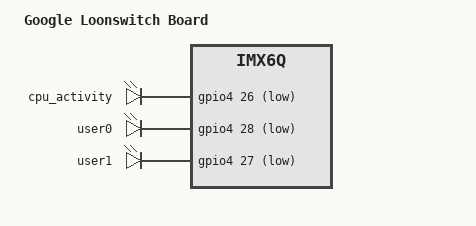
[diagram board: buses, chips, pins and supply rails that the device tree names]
/*
 * Copyright 2013 Freescale Semiconductor, Inc.
 *
 * Author: Fabio Estevam <fabio.estevam@freescale.com>
 *
 * This program is free software; you can redistribute it and/or modify
 * it under the terms of the GNU General Public License version 2 as
 * published by the Free Software Foundation.
 *
 */
/dts-v1/;
#include "imx6q.dtsi"
#include "imx6qdl-loonswitch.dtsi"
#include <dt-bindings/gpio/gpio.h>

/ {
	model = "Google Loonswitch Board";
	compatible = "fsl,imx6q";

	leds {
		compatible = "gpio-leds";
		cpuact {
			label = "cpu_activity";
			gpios = <&gpio4 26 1>;
			linux,default-trigger = "heartbeat";
			default-state = "on";
		};
		user0 {
			label = "user0";
			gpios = <&gpio4 28 1>;
			default-state = "on";
		};
		user1 {
			label = "user1";
			gpios = <&gpio4 27 1>;
			default-state = "on";
		};
	};
};

&iomuxc {
	pinctrl-names = "default";
	pinctrl-0 = <&pinctrl_hog>;

	hog {
		pinctrl_hog: hoggrp {
			fs,pins = <
				MX6QDL_PAD_EIM_RW__GPIO2_IO26		0x80000000	/* OUTPUT, BCM_PWREN, ACTIVE HIGH */
				MX6QDL_PAD_EIM_OE__GPIO2_IO25		0x80000000	/* OUTPUT, WIFI_5V_PWREN, ACTIVE HIGH */
				MX6QDL_PAD_EIM_CS0__GPIO2_IO23		0x80000000	/* OUTPUT, WIFI_PWREN, ACTIVE HIGH */
				MX6QDL_PAD_EIM_CS1__GPIO2_IO24		0x80000000	/* INPUT, LM5056_ALERTn, ACTIVE LOW */
				MX6QDL_PAD_SD1_DAT1__GPIO1_IO17 	0x80000000	/* OUTPUT, HEATER_DISABLE, ACTIVE HIGH */
				MX6QDL_PAD_KEY_COL0__GPIO4_IO06 	0x80000000	/* OUTPUT, CAN LOOPBACK, ACTIVE HIGH */
				MX6QDL_PAD_ENET_RXD0__GPIO1_IO27	0x80000000	/* INPUT, PEX_ERR#, ACTIVE LOW */
				MX6QDL_PAD_GPIO_7__GPIO1_IO07		0x80000000	/* INPUT, I210_ALERTN, ACTIVE LOW */
				MX6QDL_PAD_GPIO_8__GPIO1_IO08		0x80000000	/* INPUT, OCS_N2, ACTIVE LOW */
				MX6QDL_PAD_GPIO_9__GPIO1_IO09		0x80000000	/* OUTPUT, SC_RESET, ACTIVE HIGH */
				MX6QDL_PAD_GPIO_16__GPIO7_IO11		0x80000000	/* INPUT, I210_WAKEN, ACTIVE LOW */
				MX6QDL_PAD_GPIO_18__GPIO7_IO13		0x80000000	/* INPUT, PEX_INTA#, ACTIVE LOW */
				MX6QDL_PAD_GPIO_19__GPIO4_IO05		0x80000000	/* OUTPUT, USB_HUB_RESET_B, ACTIVE LOW */
				MX6QDL_PAD_NANDF_CS0__GPIO6_IO11	0x80000000	/* INPUT, CON_GPIO0, ACTIVE HIGH */
				MX6QDL_PAD_NANDF_CS1__GPIO6_IO14	0x80000000	/* INPUT, CON_GPIO1, ACTIVE HIGH */
				MX6QDL_PAD_NANDF_CS2__GPIO6_IO15	0x80000000	/* INPUT, CON_GPIO2, ACTIVE HIGH */
				MX6QDL_PAD_NANDF_CS3__GPIO6_IO16	0x80000000	/* INPUT, CON_GPIO3, ACTIVE HIGH */
				MX6QDL_PAD_NANDF_D0__GPIO2_IO00		0x80000000	/* INPUT, CON_GPIO4, ACTIVE HIGH */
				MX6QDL_PAD_NANDF_D1__GPIO2_IO01		0x80000000	/* INPUT, CON_GPIO5, ACTIVE HIGH */
				MX6QDL_PAD_EIM_EB1__GPIO2_IO29		0x80000000	/* OUTPUT, BCM_PCIE_WAKEn, ACTIVE LOW */
			>;
		};
	};	
};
